# MWPR1516 register map
Vendor: Freescale Semiconductor, Inc.; Series: Kinetis; File version: 1.6
CPU: CM0PLUS r0p0, little endian, no MPU, no FPU, VTOR, 2 interrupt priority bits
Registers are 8-bit, read-write, reset 0x0 unless marked. A register's access mark holds for its fields unless they carry their own. Offsets are from the block's base; [hi:lo] are bit positions.

## IRQ — Interrupt
Base 0x40031000; register names take the prefix IRQ_
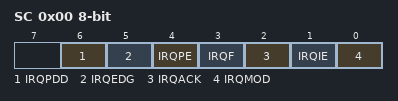
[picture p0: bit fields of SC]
0x00 SC — Interrupt Pin Request Status and Control Register
  [6] IRQPDD — Interrupt Request (IRQ) Pull Device Disable
    0=IRQ pull device enabled if IRQPE = 1; 1=IRQ pull device disabled if IRQPE = 1
  [5] IRQEDG — Interrupt Request (IRQ) Edge Select
    0=IRQ is falling-edge or falling-edge/low-level sensitive; 1=IRQ is rising-edge or rising-edge/high-level sensitive
  [4] IRQPE — IRQ Pin Enable
    0=IRQ pin function is disabled; 1=IRQ pin function is enabled
  [3] IRQF ro — IRQ Flag
    0=No IRQ request; 1=IRQ event is detected
  [2] IRQACK wo — IRQ Acknowledge
  [1] IRQIE — IRQ Interrupt Enable
    0=Interrupt request when IRQF set is disabled (use polling); 1=Interrupt requested whenever IRQF = 1
  [0] IRQMOD — IRQ Detection Mode
    0=IRQ event is detected only on falling/rising edges; 1=IRQ event is detected on falling/rising edges and low/high levels

## FSKDT — FSK Demodulation Timer
Base 0x40034000; register names take the prefix FSKDT_
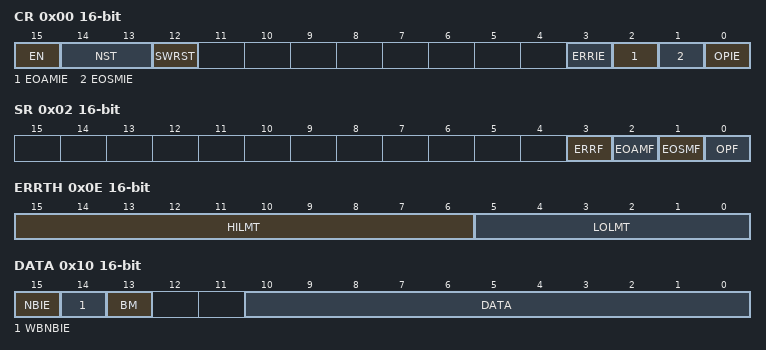
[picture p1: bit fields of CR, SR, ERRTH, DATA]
0x00 CR 16-bit — Control Register
  [15] EN — FSK demodulation Enable
    0=FSK demodulation is disabled; 1=FSK demodulation is enabled
  [14:13] NST — Number of Shift Times to measure
    0=4 cycles of FSK are grouped in one phase; 1=8 cycles of FSK are grouped in one phase; 2=16 cycles of FSK are grouped in one phase; 3=32 cycles of FSK are grouped in one phase
  [12] SWRST wo — Software Reset
  [3] ERRIE — Interrupt Enable when Error happens
    0=Interrupt is not enabled when an error happens; 1=Interrupt is enabled when an error happens
  [2] EOAMIE — End-Of-All phases Measurement Interrupt Enable
    0=End-of-all 3-phase measurement interrupt is disabled; 1=End-of-all 3-phase measurement interrupt is enabled
  [1] EOSMIE — End-Of-Single phase Measurement Interrupt Enable
    0=End-of-single phase measurement interrupt is disabled; 1=End-of-single phase measurement interrupt is enabled
  [0] OPIE — Out-of-Period Interrupt Enable
    0=Out-of-Period Interrupt is disabled; 1=Out-of-Period Interrupt is enabled
0x02 SR 16-bit — Status Register
  [3] ERRF — Error happens during measurement
    0=No error happens; 1=Error happens and the software needs to check the status registers to confirm which is the possible cause to the error
  [2] EOAMF — End-Of-All Measurement Flag
    0=The 3-phase measurement is not completed; 1=A complete 3-phase measurement finishes
  [1] EOSMF — End-Of-Single Measurement Flag
    0=The one-phase measurement is not completed; 1=A complete one-phase measurement finishes
  [0] OPF — Out-of-Period Flag
    0=The counter value hasn't the changes larger than the threshold; 1=The counter value has significant change that larger than the threshold
0x04 PH0 16-bit ro — Phase0 counter value
  [15:0] PH0CNTR — Counter values for Phase 0 measurement
0x06 PH1 16-bit ro — Phase1 counter value
  [15:0] PH1CNTR — Counter values for Phase 1 measurement
0x08 PH2 16-bit ro — Phase2 counter value
  [15:0] PH2CNTR — Counter values for phase 2 measurement
0x0A CURPOS 16-bit ro — Current Position Register
  [15:0] CURPOS — Current Position
0x0C OPCTH 16-bit — Out-of-Period Counter Threshold Register
  [9:0] OPCTH — Out-of-Period Counter threshold
0x0E ERRTH 16-bit — Error Threshold Register
  [15:6] HILMT — High Limitation
  [5:0] LOLMT — Low Limitation
0x10 DATA 16-bit — Demodulation Data Register
  [15] NBIE — New Bit decoding Interrupt Enable
    0=Interrupt is not enabled when decoding one new bit of FSK signal; 1=Interrupt is enabled when decoding one new bit of FSK signal
  [14] WBNBIE — Whole Byte Bits decoding finish Interrupt Enable
    0=Interrupt is not enabled when decoding one whole byte of FSK signal; 1=Interrupt is enabled when decoding one whole byte of FSK signal
  [13] BM — Package Byte Mode
    0=11-bit mode; 1=8-bit mode
  [10:0] DATA ro — The demodulated FSK data
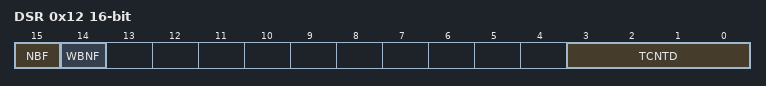
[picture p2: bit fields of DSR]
0x12 DSR 16-bit — Demodulation Data Status Register
  [15] NBF — New Bit shift to DATA Flag
  [14] WBNF — New Whole Byte decoded Flag
  [3:0] TCNTD ro — Total Count for bits that have been Decoded

## Notices in the file
Redistribution and use in source and binary forms, with or without modification,
are permitted provided that the following conditions are met:
o Redistributions of source code must retain the above copyright notice, this list
of conditions and the following disclaimer.
o Redistributions in binary form must reproduce the above copyright notice, this
list of conditions and the following disclaimer in the documentation and/or
other materials provided with the distribution.
o Neither the name of Freescale Semiconductor, Inc. nor the names of its
contributors may be used to endorse or promote products derived from this
software without specific prior written permission.
THIS SOFTWARE IS PROVIDED BY THE COPYRIGHT HOLDERS AND CONTRIBUTORS "AS IS" AND
ANY EXPRESS OR IMPLIED WARRANTIES, INCLUDING, BUT NOT LIMITED TO, THE IMPLIED
WARRANTIES OF MERCHANTABILITY AND FITNESS FOR A PARTICULAR PURPOSE ARE
DISCLAIMED. IN NO EVENT SHALL THE COPYRIGHT HOLDER OR CONTRIBUTORS BE LIABLE FOR
ANY DIRECT, INDIRECT, INCIDENTAL, SPECIAL, EXEMPLARY, OR CONSEQUENTIAL DAMAGES
(INCLUDING, BUT NOT LIMITED TO, PROCUREMENT OF SUBSTITUTE GOODS OR SERVICES;
LOSS OF USE, DATA, OR PROFITS; OR BUSINESS INTERRUPTION) HOWEVER CAUSED AND ON
ANY THEORY OF LIABILITY, WHETHER IN CONTRACT, STRICT LIABILITY, OR TORT
(INCLUDING NEGLIGENCE OR OTHERWISE) ARISING IN ANY WAY OUT OF THE USE OF THIS
SOFTWARE, EVEN IF ADVISED OF THE POSSIBILITY OF SUCH DAMAGE.
